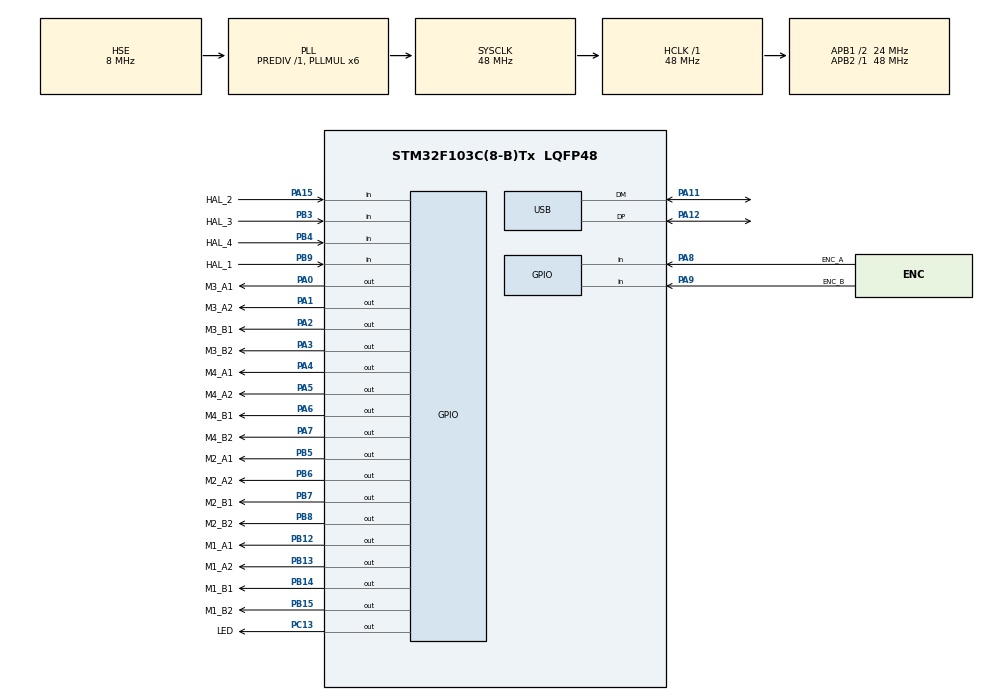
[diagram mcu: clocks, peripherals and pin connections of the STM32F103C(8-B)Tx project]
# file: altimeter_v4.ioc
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Mcu.Family=STM32F1
Mcu.Name=STM32F103C(8-B)Tx
Mcu.Package=LQFP48
NVIC.PriorityGroup=NVIC_PRIORITYGROUP_4
NVIC.TIM2_IRQn=true\:0\:0\:false\:false\:true\:true\:true
NVIC.USB_LP_CAN1_RX0_IRQn=true\:0\:0\:false\:false\:true\:false\:true
PA0-WKUP.GPIO_Label=M3_A1
PA0-WKUP.Signal=GPIO_Output
PA1.GPIO_Label=M3_A2
PA1.Signal=GPIO_Output
PA11.Mode=Device
PA11.Signal=USB_DM
PA12.Mode=Device
PA12.Signal=USB_DP
PA15.GPIO_Label=HAL_2
PA15.GPIO_PuPd=GPIO_PULLUP
PA15.Signal=GPIO_Input
PA2.GPIO_Label=M3_B1
PA2.Signal=GPIO_Output
PA3.GPIO_Label=M3_B2
PA3.Signal=GPIO_Output
PA4.GPIO_Label=M4_A1
PA4.Signal=GPIO_Output
PA5.GPIO_Label=M4_A2
PA5.Signal=GPIO_Output
PA6.GPIO_Label=M4_B1
PA6.Signal=GPIO_Output
PA7.GPIO_Label=M4_B2
PA7.Signal=GPIO_Output
PA8.GPIO_Label=ENC_A
PA8.GPIO_PuPd=GPIO_PULLUP
PA8.Signal=GPIO_Input
PA9.GPIO_Label=ENC_B
PA9.GPIO_PuPd=GPIO_PULLUP
PA9.Signal=GPIO_Input
PB12.GPIO_Label=M1_A1
PB12.Signal=GPIO_Output
PB13.GPIO_Label=M1_A2
PB13.Signal=GPIO_Output
PB14.GPIO_Label=M1_B1
PB14.Signal=GPIO_Output
PB15.GPIO_Label=M1_B2
PB15.Signal=GPIO_Output
PB3.GPIO_Label=HAL_3
PB3.GPIO_PuPd=GPIO_PULLUP
PB3.Signal=GPIO_Input
PB4.GPIO_Label=HAL_4
PB4.GPIO_PuPd=GPIO_PULLUP
PB4.Signal=GPIO_Input
PB5.GPIO_Label=M2_A1
PB5.Signal=GPIO_Output
PB6.GPIO_Label=M2_A2
PB6.Signal=GPIO_Output
PB7.GPIO_Label=M2_B1
PB7.Signal=GPIO_Output
PB8.GPIO_Label=M2_B2
PB8.Signal=GPIO_Output
PB9.GPIO_Label=HAL_1
PB9.GPIO_PuPd=GPIO_PULLUP
PB9.Signal=GPIO_Input
PC13-TAMPER-RTC.GPIO_Label=LED
PC13-TAMPER-RTC.Signal=GPIO_Output
PC14-OSC32_IN.Mode=LSE-External-Oscillator
PC14-OSC32_IN.Signal=RCC_OSC32_IN
PC15-OSC32_OUT.Mode=LSE-External-Oscillator
PC15-OSC32_OUT.Signal=RCC_OSC32_OUT
PD0-OSC_IN.Mode=HSE-External-Oscillator
PD0-OSC_IN.Signal=RCC_OSC_IN
PD1-OSC_OUT.Mode=HSE-External-Oscillator
PD1-OSC_OUT.Signal=RCC_OSC_OUT
ProjectManager.HeapSize=0x200
ProjectManager.StackSize=0x400
ProjectManager.TargetToolchain=STM32CubeIDE
RCC.AHBFreq_Value=48000000
RCC.APB1CLKDivider=RCC_HCLK_DIV2
RCC.APB1Freq_Value=24000000
RCC.APB1TimFreq_Value=48000000
RCC.APB2Freq_Value=48000000
RCC.APB2TimFreq_Value=48000000
RCC.HCLKFreq_Value=48000000
RCC.PLLMUL=RCC_PLL_MUL6
RCC.SYSCLKFreq_VALUE=48000000
RCC.SYSCLKSource=RCC_SYSCLKSOURCE_PLLCLK
RCC.USBFreq_Value=48000000
TIM2.AutoReloadPreload=TIM_AUTORELOAD_PRELOAD_ENABLE
TIM2.Period=7200
TIM2.Prescaler=1000
USB_DEVICE.CLASS_NAME_FS=CDC
USB_DEVICE.VirtualMode=Cdc
USB_DEVICE.VirtualModeFS=Cdc_FS
VP_SYS_VS_ND.Mode=No_Debug
VP_TIM2_VS_ClockSourceINT.Mode=Internal
VP_USB_DEVICE_VS_USB_DEVICE_CDC_FS.Mode=CDC_FS
board=custom

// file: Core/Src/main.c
/* USER CODE BEGIN Header */
/**
  ******************************************************************************
  * @file           : main.c
  * @brief          : Main program body
  ******************************************************************************
  * @attention
  *
  * <h2><center>&copy; Copyright (c) 2021 STMicroelectronics.
  * All rights reserved.</center></h2>
  *
  * This software component is licensed by ST under Ultimate Liberty license
  * SLA0044, the "License"; You may not use this file except in compliance with
  * the License. You may obtain a copy of the License at:
  *                             www.st.com/SLA0044
  *
  ******************************************************************************
  */
/* USER CODE END Header */
#include "main.h"
#include "usb_device.h"
#include "motor.h"
#include "com.h"

/* USER CODE BEGIN Includes */
void USB_DEVICE_MasterHardReset(void)

{

    GPIO_InitTypeDef GPIO_InitStruct;
    GPIO_InitStruct.Pin = GPIO_PIN_12;
    GPIO_InitStruct.Mode = GPIO_MODE_OUTPUT_PP;
    GPIO_InitStruct.Pull = GPIO_PULLDOWN;
    GPIO_InitStruct.Speed = GPIO_SPEED_FREQ_HIGH;
    HAL_GPIO_Init(GPIOA, &GPIO_InitStruct);
    HAL_GPIO_WritePin(GPIOA,GPIO_PIN_12,0);
    HAL_Delay(1000);

}
/* USER CODE END Includes */

TIM_HandleTypeDef htim2;

void SystemClock_Config(void);
static void MX_GPIO_Init(void);
static void MX_TIM2_Init(void);

int main(void)
{

  /* MCU Configuration--------------------------------------------------------*/

  /* Reset of all peripherals, Initializes the Flash interface and the Systick. */
  HAL_Init();

  /* Configure the system clock */
  SystemClock_Config();

  /* Initialize all configured peripherals */
  MX_GPIO_Init();
  USB_DEVICE_MasterHardReset();
  MX_USB_DEVICE_Init();
  MX_TIM2_Init();

  /* USER CODE BEGIN 2 */
  tx_stack_init();

  /* USER CODE END 2 */

  //homeAll();
  /* Infinite loop */
  while (1)
  {
	tx_stack_process();
	//HAL_Delay(2000);
	//HAL_GPIO_TogglePin(LED_GPIO_Port, LED_Pin);
	//heartbeatISR();
	//moveStepper(0,10);
	//moveStepper(1,1);
	//moveStepper(2,-5);
	//moveStepper(3,-5);
  }
}

uint16_t cdc_isr_prescaler = 1600;
uint16_t cdc_isr_timer = 0;

void HAL_TIM_PeriodElapsedCallback(TIM_HandleTypeDef* htim)
{
	stepperServiceRoutine();

	cdc_isr_timer ++;
	if (cdc_isr_timer == cdc_isr_prescaler){
		cdc_isr_timer = 0;

	}
}

void SystemClock_Config(void)
{
  RCC_OscInitTypeDef RCC_OscInitStruct = {0};
  RCC_ClkInitTypeDef RCC_ClkInitStruct = {0};
  RCC_PeriphCLKInitTypeDef PeriphClkInit = {0};

  /** Initializes the RCC Oscillators according to the specified parameters
  * in the RCC_OscInitTypeDef structure.
  */
  RCC_OscInitStruct.OscillatorType = RCC_OSCILLATORTYPE_HSE;
  RCC_OscInitStruct.HSEState = RCC_HSE_ON;
  RCC_OscInitStruct.HSEPredivValue = RCC_HSE_PREDIV_DIV1;
  RCC_OscInitStruct.HSIState = RCC_HSI_ON;
  RCC_OscInitStruct.PLL.PLLState = RCC_PLL_ON;
  RCC_OscInitStruct.PLL.PLLSource = RCC_PLLSOURCE_HSE;
  RCC_OscInitStruct.PLL.PLLMUL = RCC_PLL_MUL6;
  if (HAL_RCC_OscConfig(&RCC_OscInitStruct) != HAL_OK)
  {
    Error_Handler();
  }
  /** Initializes the CPU, AHB and APB buses clocks
  */
  RCC_ClkInitStruct.ClockType = RCC_CLOCKTYPE_HCLK|RCC_CLOCKTYPE_SYSCLK
                              |RCC_CLOCKTYPE_PCLK1|RCC_CLOCKTYPE_PCLK2;
  RCC_ClkInitStruct.SYSCLKSource = RCC_SYSCLKSOURCE_PLLCLK;
  RCC_ClkInitStruct.AHBCLKDivider = RCC_SYSCLK_DIV1;
  RCC_ClkInitStruct.APB1CLKDivider = RCC_HCLK_DIV2;
  RCC_ClkInitStruct.APB2CLKDivider = RCC_HCLK_DIV1;

  if (HAL_RCC_ClockConfig(&RCC_ClkInitStruct, FLASH_LATENCY_1) != HAL_OK)
  {
    Error_Handler();
  }
  PeriphClkInit.PeriphClockSelection = RCC_PERIPHCLK_USB;
  PeriphClkInit.UsbClockSelection = RCC_USBCLKSOURCE_PLL;
  if (HAL_RCCEx_PeriphCLKConfig(&PeriphClkInit) != HAL_OK)
  {
    Error_Handler();
  }
}

static void MX_TIM2_Init(void)
{

  TIM_ClockConfigTypeDef sClockSourceConfig = {0};
  TIM_MasterConfigTypeDef sMasterConfig = {0};

  htim2.Instance = TIM2;
  htim2.Init.Prescaler = 10;
  htim2.Init.CounterMode = TIM_COUNTERMODE_UP;
  htim2.Init.Period = 5000;
  htim2.Init.ClockDivision = TIM_CLOCKDIVISION_DIV1;
  htim2.Init.AutoReloadPreload = TIM_AUTORELOAD_PRELOAD_ENABLE;
  if (HAL_TIM_Base_Init(&htim2) != HAL_OK)
  {
    Error_Handler();
  }
  sClockSourceConfig.ClockSource = TIM_CLOCKSOURCE_INTERNAL;
  if (HAL_TIM_ConfigClockSource(&htim2, &sClockSourceConfig) != HAL_OK)
  {
    Error_Handler();
  }
  sMasterConfig.MasterOutputTrigger = TIM_TRGO_RESET;
  sMasterConfig.MasterSlaveMode = TIM_MASTERSLAVEMODE_DISABLE;
  if (HAL_TIMEx_MasterConfigSynchronization(&htim2, &sMasterConfig) != HAL_OK)
  {
    Error_Handler();
  }
  /* USER CODE BEGIN TIM2_Init 2 */
  HAL_TIM_Base_Start_IT(&htim2);
  /* USER CODE END TIM2_Init 2 */

}

static void MX_GPIO_Init(void)
{
  GPIO_InitTypeDef GPIO_InitStruct = {0};

  /* GPIO Ports Clock Enable */
  __HAL_RCC_GPIOC_CLK_ENABLE();
  __HAL_RCC_GPIOD_CLK_ENABLE();
  __HAL_RCC_GPIOA_CLK_ENABLE();
  __HAL_RCC_GPIOB_CLK_ENABLE();

  /*Configure GPIO pin Output Level */
  HAL_GPIO_WritePin(LED_GPIO_Port, LED_Pin, GPIO_PIN_RESET);

  /*Configure GPIO pin Output Level */
  HAL_GPIO_WritePin(GPIOA, M3_A1_Pin|M3_A2_Pin|M3_B1_Pin|M3_B2_Pin
                          |M4_A1_Pin|M4_A2_Pin|M4_B1_Pin|M4_B2_Pin, GPIO_PIN_RESET);

  /*Configure GPIO pin Output Level */
  HAL_GPIO_WritePin(GPIOB, M1_A1_Pin|M1_A2_Pin|M1_B1_Pin|M1_B2_Pin
                          |M2_A1_Pin|M2_A2_Pin|M2_B1_Pin|M2_B2_Pin, GPIO_PIN_RESET);

  /*Configure GPIO pin : LED_Pin */
  GPIO_InitStruct.Pin = LED_Pin;
  GPIO_InitStruct.Mode = GPIO_MODE_OUTPUT_PP;
  GPIO_InitStruct.Pull = GPIO_NOPULL;
  GPIO_InitStruct.Speed = GPIO_SPEED_FREQ_LOW;
  HAL_GPIO_Init(LED_GPIO_Port, &GPIO_InitStruct);

  /*Configure GPIO pins : M3_A1_Pin M3_A2_Pin M3_B1_Pin M3_B2_Pin
                           M4_A1_Pin M4_A2_Pin M4_B1_Pin M4_B2_Pin */
  GPIO_InitStruct.Pin = M3_A1_Pin|M3_A2_Pin|M3_B1_Pin|M3_B2_Pin
                          |M4_A1_Pin|M4_A2_Pin|M4_B1_Pin|M4_B2_Pin;
  GPIO_InitStruct.Mode = GPIO_MODE_OUTPUT_PP;
  GPIO_InitStruct.Pull = GPIO_NOPULL;
  GPIO_InitStruct.Speed = GPIO_SPEED_FREQ_LOW;
  HAL_GPIO_Init(GPIOA, &GPIO_InitStruct);

  /*Configure GPIO pins : M1_A1_Pin M1_A2_Pin M1_B1_Pin M1_B2_Pin
                           M2_A1_Pin M2_A2_Pin M2_B1_Pin M2_B2_Pin */
  GPIO_InitStruct.Pin = M1_A1_Pin|M1_A2_Pin|M1_B1_Pin|M1_B2_Pin
                          |M2_A1_Pin|M2_A2_Pin|M2_B1_Pin|M2_B2_Pin;
  GPIO_InitStruct.Mode = GPIO_MODE_OUTPUT_PP;
  GPIO_InitStruct.Pull = GPIO_NOPULL;
  GPIO_InitStruct.Speed = GPIO_SPEED_FREQ_LOW;
  HAL_GPIO_Init(GPIOB, &GPIO_InitStruct);

  /*Configure GPIO pins : ENC_A_Pin ENC_B_Pin  */
  GPIO_InitStruct.Pin = ENC_A_Pin|ENC_B_Pin;
  GPIO_InitStruct.Mode = GPIO_MODE_INPUT;
  GPIO_InitStruct.Pull = GPIO_PULLUP;
  GPIO_InitStruct.Speed = GPIO_SPEED_FREQ_LOW;
  HAL_GPIO_Init(GPIOA, &GPIO_InitStruct);

  /*Configure GPIO pins : HAL_2_Pin HAL_3_Pin HAL_4_Pin HAL_1_Pin */
  GPIO_InitStruct.Pin = HAL_3_Pin|HAL_4_Pin|HAL_1_Pin|HAL_2_Pin;
  GPIO_InitStruct.Mode = GPIO_MODE_INPUT;
  GPIO_InitStruct.Pull = GPIO_PULLUP;
  GPIO_InitStruct.Speed = GPIO_SPEED_FREQ_LOW;
  HAL_GPIO_Init(GPIOB, &GPIO_InitStruct);

}

void Error_Handler(void)
{
  __disable_irq();
  while (1)
  {
  }
}

/************************ (C) COPYRIGHT STMicroelectronics *****END OF FILE****/
